# regs-internal register map
Registers from a debugger description file.
Registers are 32-bit, access not given, no defined reset value unless marked. A register's access mark holds for its fields unless they carry their own. Addresses are absolute; registers are grouped by the start of their names; lines under a group give offsets from that group; [hi:lo] are bit positions; {n}, {i} and the like mark numbered series; 'fields as' and 'values as' point back to an identical list; <NAME> marks a mode.

## SLEEPTMR
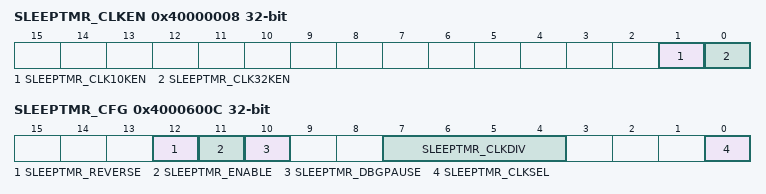
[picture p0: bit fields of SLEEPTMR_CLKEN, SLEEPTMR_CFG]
0x40000008 SLEEPTMR_CLKEN
  [1] SLEEPTMR_CLK10KEN, [0] SLEEPTMR_CLK32KEN
0x4000600C SLEEPTMR_CFG
  [12] SLEEPTMR_REVERSE, [11] SLEEPTMR_ENABLE, [10] SLEEPTMR_DBGPAUSE, [7:4] SLEEPTMR_CLKDIV, [0] SLEEPTMR_CLKSEL
0x40006010 SLEEPTMR_CNTH
  [15:0] SLEEPTMR_CNTH_FIELD
0x40006014 SLEEPTMR_CNTL
  [15:0] SLEEPTMR_CNTL_FIELD
0x40006018 SLEEPTMR_CMPAH
  [15:0] SLEEPTMR_CMPAH_FIELD
0x4000601C SLEEPTMR_CMPAL
  [15:0] SLEEPTMR_CMPAL_FIELD
0x40006020 SLEEPTMR_CMPBH
  [15:0] SLEEPTMR_CMPBH_FIELD
0x40006024 SLEEPTMR_CMPBL
  [15:0] SLEEPTMR_CMPBL_FIELD

## SFR
0x40000000 HV_SPARE
  [7:0] HV_SPARE
0x40000004 EVENT_CTRL
  [1] LV_FREEZE
0x4000000C CLKRC_TUNE
  [3:0] CLKRC_TUNE_FIELD
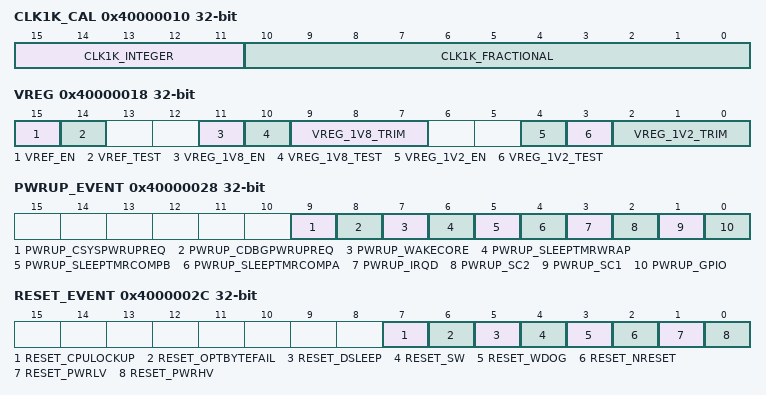
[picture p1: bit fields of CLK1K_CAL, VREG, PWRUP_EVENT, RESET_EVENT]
0x40000010 CLK1K_CAL
  [15:11] CLK1K_INTEGER, [10:0] CLK1K_FRACTIONAL
0x40000014 REGEN_DSLEEP
  [0] REGEN_DSLEEP_FIELD
0x40000018 VREG
  [15] VREF_EN, [14] VREF_TEST, [11] VREG_1V8_EN, [10] VREG_1V8_TEST, [9:7] VREG_1V8_TRIM, [4] VREG_1V2_EN, [3] VREG_1V2_TEST, [2:0] VREG_1V2_TRIM
0x40000028 PWRUP_EVENT
  [9] PWRUP_CSYSPWRUPREQ, [8] PWRUP_CDBGPWRUPREQ, [7] PWRUP_WAKECORE, [6] PWRUP_SLEEPTMRWRAP, [5] PWRUP_SLEEPTMRCOMPB, [4] PWRUP_SLEEPTMRCOMPA, [3] PWRUP_IRQD, [2] PWRUP_SC2, [1] PWRUP_SC1, [0] PWRUP_GPIO
0x4000002C RESET_EVENT
  [7] RESET_CPULOCKUP, [6] RESET_OPTBYTEFAIL, [5] RESET_DSLEEP, [4] RESET_SW, [3] RESET_WDOG, [2] RESET_NRESET, [1] RESET_PWRLV, [0] RESET_PWRHV
0x40000030 DBG_MBOX
  [15:0] DBG_MBOX
0x40000034 CPWRUPREQ_STATUS
  [0] CPWRUPREQ
0x40000038 CSYSPWRUPREQ_STATUS
  [0] CSYSPWRUPREQ
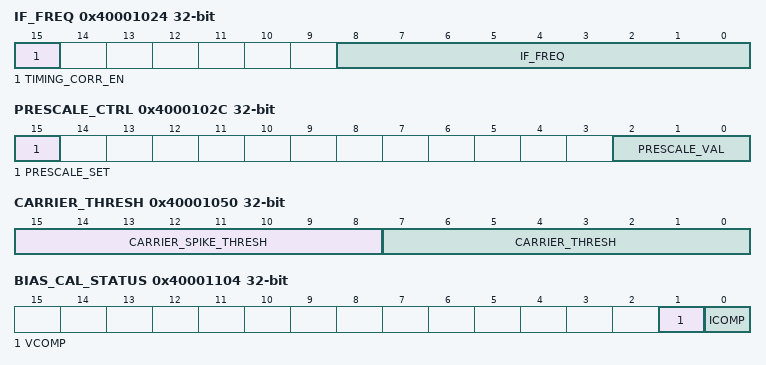
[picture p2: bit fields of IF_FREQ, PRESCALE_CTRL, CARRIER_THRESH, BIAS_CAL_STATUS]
0x40001024 IF_FREQ
  [15] TIMING_CORR_EN, [8:0] IF_FREQ
0x4000102C PRESCALE_CTRL
  [15] PRESCALE_SET, [2:0] PRESCALE_VAL
0x40001048 PD_DITHER_EN
  [0] PD_DITHER_EN
0x40001050 CARRIER_THRESH
  [15:8] CARRIER_SPIKE_THRESH, [7:0] CARRIER_THRESH
0x4000105C IN_LOCK_EN
  [0] IN_LOCK_EN
0x400010AC MIXER_GAIN_STEP
  [3:0] MIXER_GAIN_STEP
0x400010BC CCA_MODE
  [1:0] CCA_MODE
0x40001104 BIAS_CAL_STATUS
  [1] VCOMP, [0] ICOMP
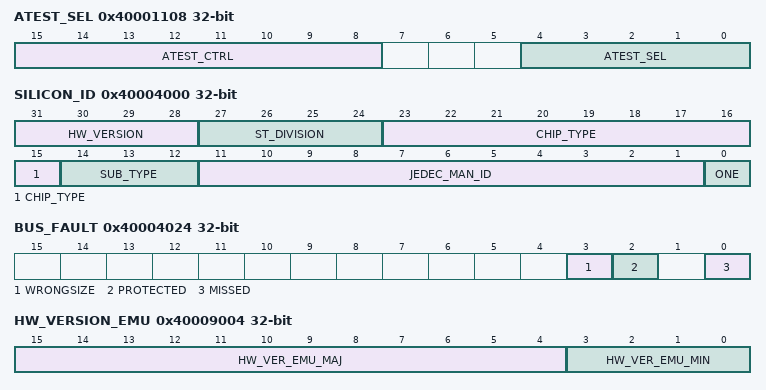
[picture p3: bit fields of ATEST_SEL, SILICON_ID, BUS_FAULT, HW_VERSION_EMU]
0x40001108 ATEST_SEL
  [15:8] ATEST_CTRL, [4:0] ATEST_SEL
0x40001114 NOISE_EN
  [0] NOISE_EN
0x40002090 PAN_ID
  [15:0] PAN_ID
0x40002094 SHORT_ADDR
  [15:0] SHORT_ADDR
0x400020C4 PANID_COUNT
  [15:0] PANID_COUNT
0x400020C8 NONPAN_COUNT
  [15:0] NONPAN_COUNT
0x40003028 PT
0x40003030 CT
0x40004000 SILICON_ID
  [31:28] HW_VERSION, [27:24] ST_DIVISION, [23:15] CHIP_TYPE, [14:12] SUB_TYPE, [11:1] JEDEC_MAN_ID, [0] ONE
0x40004008 OSCHF_TUNE
  [4:0] OSCHF_TUNE_FIELD
0x40004020 CPU_CLKSEL
  [0] CPU_CLKSEL_FIELD
0x40004024 BUS_FAULT
  [3] WRONGSIZE, [2] PROTECTED, [0] MISSED
0x40004028 PCTRACE_SEL
  [0] PCTRACE_SEL_FIELD
0x40004034 LV_SPARE
  [7:0] LV_SPARE
0x40008020 WRPROT
  [31:0] WRP
0x40009000 I_AM_AN_EMULATOR
  [0] I_AM_AN_EMULATOR
0x40009004 HW_VERSION_EMU
  [15:4] HW_VER_EMU_MAJ, [3:0] HW_VER_EMU_MIN
0x40009028 VCO_DAC_FILTER_DIS
  [0] VCO_DAC_FILTER_DIS
0x4000A024 TEST_FORCE_ALL_INT
  [0] FORCE_ALL_INT

## Notices in the file
Copyright 2008 by Ember Corporation. All rights reserved. *80
